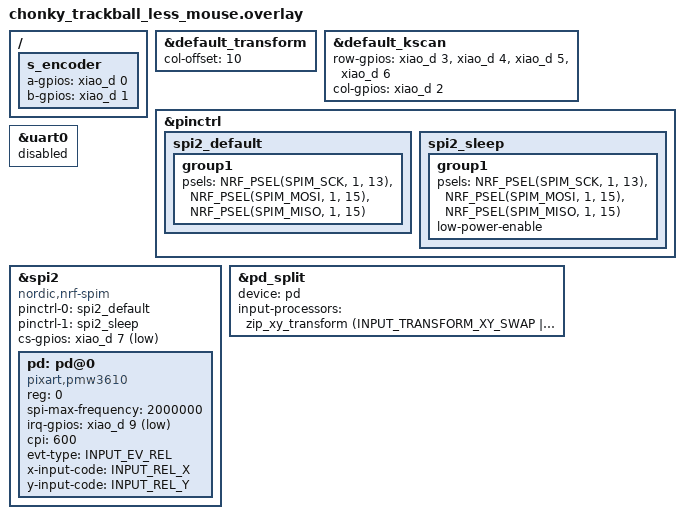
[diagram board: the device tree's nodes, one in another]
/*
 * Copyright (c) 2020 Pete Johanson
 *
 * SPDX-License-Identifier: MIT
 */

#include "chonky_trackball_less.dtsi"
#include <dt-bindings/zmk/input_transform.h>
#include <input/processors.dtsi>

&default_transform {
    col-offset = <10>;
};

&default_kscan {
    row-gpios
            = <&xiao_d 3 GPIO_ACTIVE_HIGH>
            , <&xiao_d 4  GPIO_ACTIVE_HIGH>
            , <&xiao_d 5  GPIO_ACTIVE_HIGH>
            , <&xiao_d 6 GPIO_ACTIVE_HIGH>
            ;

    col-gpios
			= <&xiao_d 2 (GPIO_ACTIVE_HIGH | GPIO_PULL_DOWN)>

        ;
};

&pinctrl {
	spi2_default: spi2_default {
		group1 {
			psels = <NRF_PSEL(SPIM_SCK, 1, 13)>,
							<NRF_PSEL(SPIM_MOSI, 1, 15)>,
							<NRF_PSEL(SPIM_MISO, 1, 15)>;
		};
	};
	spi2_sleep: spi2_sleep {
		group1 {
			psels = <NRF_PSEL(SPIM_SCK, 1, 13)>,
							<NRF_PSEL(SPIM_MOSI, 1, 15)>,
							<NRF_PSEL(SPIM_MISO, 1, 15)>;
			low-power-enable;
		};
	};
};

// release gpio1 11 & 12 from xiao_ble-pinctrl.dtsi
// for &trackball { irq-gpios }
&uart0 {
	status = "disabled";
};

&spi2 {
	compatible = "nordic,nrf-spim";
	status = "okay";
	pinctrl-0 = <&spi2_default>;
	pinctrl-1 = <&spi2_sleep>;
	pinctrl-names = "default", "sleep";
	cs-gpios = <&xiao_d 7 GPIO_ACTIVE_LOW>;

	pd: pd@0 {
		compatible = "pixart,pmw3610";
		status = "okay";
		reg = <0>;
		spi-max-frequency = <2000000>;

		// pmw3610 driver parameters
		irq-gpios = <&xiao_d 9 (GPIO_ACTIVE_LOW | GPIO_PULL_UP)>;
		cpi = <600>;
		evt-type = <INPUT_EV_REL>;
		x-input-code = <INPUT_REL_X>;
		y-input-code = <INPUT_REL_Y>;
	};
};

&pd_split {
    device = <&pd>;
    input-processors = <&zip_xy_transform (INPUT_TRANSFORM_XY_SWAP | INPUT_TRANSFORM_X_INVERT | INPUT_TRANSFORM_Y_INVERT)>;
};


/{
	s_encoder: s_encoder {
		status = "okay";
		a-gpios = <&xiao_d 0  (GPIO_ACTIVE_HIGH | GPIO_PULL_UP)>;
		b-gpios = <&xiao_d 1  (GPIO_ACTIVE_HIGH | GPIO_PULL_UP)>;
	};
};

